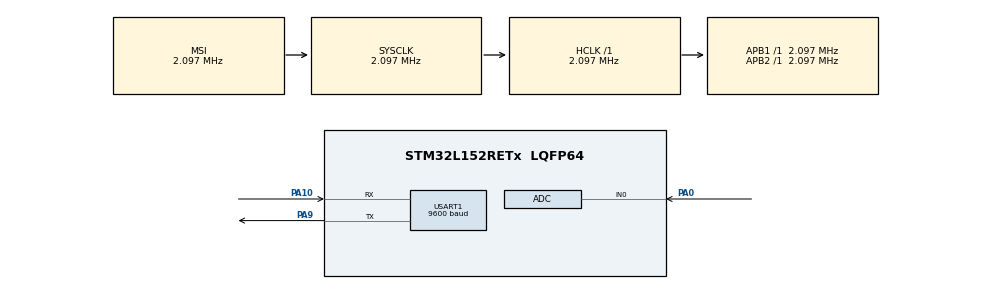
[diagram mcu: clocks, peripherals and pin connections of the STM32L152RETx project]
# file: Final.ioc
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ADC.Channel-0\#ChannelRegularConversion=ADC_CHANNEL_0
ADC.ChannelsBank=ADC_CHANNELS_BANK_A
ADC.ClockPrescaler=ADC_CLOCK_ASYNC_DIV1
ADC.ContinuousConvMode=DISABLE
ADC.DMAContinuousRequests=DISABLE
ADC.DataAlign=ADC_DATAALIGN_RIGHT
ADC.DiscontinuousConvMode=DISABLE
ADC.EOCSelection=ADC_EOC_SEQ_CONV
ADC.EnableAnalogWatchDog=false
ADC.ExternalTrigConv=ADC_SOFTWARE_START
ADC.ExternalTrigConvEdge=ADC_EXTERNALTRIGCONVEDGE_NONE
ADC.InjNumberOfConversion=0
ADC.LowPowerAutoPowerOff=ADC_AUTOPOWEROFF_DISABLE
ADC.LowPowerAutoWait=ADC_AUTOWAIT_DISABLE
ADC.NbrOfConversion=1
ADC.NbrOfConversionFlag=1
ADC.Rank-0\#ChannelRegularConversion=1
ADC.Resolution=ADC_RESOLUTION_10B
ADC.SamplingTime-0\#ChannelRegularConversion=ADC_SAMPLETIME_4CYCLES
ADC.ScanConvMode=ADC_SCAN_DISABLE
Mcu.Family=STM32L1
Mcu.Name=STM32L152RETx
Mcu.Package=LQFP64
NVIC.PriorityGroup=NVIC_PRIORITYGROUP_4
NVIC.RCC_IRQn=true\:0\:0\:false\:false\:true\:true
PA0-WKUP1.Mode=IN0
PA0-WKUP1.Signal=ADC_IN0
PA10.Mode=Asynchronous
PA10.Signal=USART1_RX
PA13.Mode=Serial_Wire
PA13.Signal=SYS_JTMS-SWDIO
PA14.Mode=Serial_Wire
PA14.Signal=SYS_JTCK-SWCLK
PA9.Mode=Asynchronous
PA9.Signal=USART1_TX
ProjectManager.HeapSize=0x200
ProjectManager.StackSize=0x400
ProjectManager.TargetToolchain=MDK-ARM V5
RCC.AHBFreq_Value=2097000
RCC.APB1Freq_Value=2097000
RCC.APB2Freq_Value=2097000
RCC.HSE_VALUE=24000000
RCC.HSI_VALUE=16000000
RCC.LSE_VALUE=32768
RCC.MSI_VALUE=2097000
RCC.SYSCLKFreq_VALUE=2097000
RCC.VCOOutputFreq_Value=48000000
USART1.BaudRate=9600
USART1.VirtualMode=VM_ASYNC
board=custom

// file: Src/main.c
/**
  ******************************************************************************
  * @file           : main.c
  * @brief          : Main program body
  ******************************************************************************
  ** This notice applies to any and all portions of this file
  * that are not between comment pairs USER CODE BEGIN and
  * USER CODE END. Other portions of this file, whether
  * inserted by the user or by software development tools
  * are owned by their respective copyright owners.
  *
  * COPYRIGHT(c) 2019 STMicroelectronics
  *
  * Redistribution and use in source and binary forms, with or without modification,
  * are permitted provided that the following conditions are met:
  *   1. Redistributions of source code must retain the above copyright notice,
  *      this list of conditions and the following disclaimer.
  *   2. Redistributions in binary form must reproduce the above copyright notice,
  *      this list of conditions and the following disclaimer in the documentation
  *      and/or other materials provided with the distribution.
  *   3. Neither the name of STMicroelectronics nor the names of its contributors
  *      may be used to endorse or promote products derived from this software
  *      without specific prior written permission.
  *
  * THIS SOFTWARE IS PROVIDED BY THE COPYRIGHT HOLDERS AND CONTRIBUTORS "AS IS"
  * AND ANY EXPRESS OR IMPLIED WARRANTIES, INCLUDING, BUT NOT LIMITED TO, THE
  * IMPLIED WARRANTIES OF MERCHANTABILITY AND FITNESS FOR A PARTICULAR PURPOSE ARE
  * DISCLAIMED. IN NO EVENT SHALL THE COPYRIGHT HOLDER OR CONTRIBUTORS BE LIABLE
  * FOR ANY DIRECT, INDIRECT, INCIDENTAL, SPECIAL, EXEMPLARY, OR CONSEQUENTIAL
  * DAMAGES (INCLUDING, BUT NOT LIMITED TO, PROCUREMENT OF SUBSTITUTE GOODS OR
  * SERVICES; LOSS OF USE, DATA, OR PROFITS; OR BUSINESS INTERRUPTION) HOWEVER
  * CAUSED AND ON ANY THEORY OF LIABILITY, WHETHER IN CONTRACT, STRICT LIABILITY,
  * OR TORT (INCLUDING NEGLIGENCE OR OTHERWISE) ARISING IN ANY WAY OUT OF THE USE
  * OF THIS SOFTWARE, EVEN IF ADVISED OF THE POSSIBILITY OF SUCH DAMAGE.
  *
  ******************************************************************************
  */
#include "main.h"
#include "stm32l1xx_hal.h"
#include "adc.h"
#include "usart.h"
#include "gpio.h"

/* USER CODE BEGIN Includes */
#include "stdio.h"
/* USER CODE END Includes */

/* USER CODE BEGIN PV */
/* Private variables ---------------------------------------------------------*/
#ifdef __GNU__
	#define PUTCHAR_PROTOTYPE int __io_putchar(int ch)
#else
	#define PUTCHAR_PROTOTYPE int fputc(int ch, FILE *f)
#endif

PUTCHAR_PROTOTYPE {
	HAL_UART_Transmit(&huart1, (uint8_t *)&ch, 1, 10);
	return ch;
}

uint16_t adcValue = 0;

//#define debug

/* USER CODE END PV */

void SystemClock_Config(void);

/* USER CODE BEGIN PFP */
/* Private function prototypes -----------------------------------------------*/

/* USER CODE END PFP */

int main(void)
{

  /* MCU Configuration----------------------------------------------------------*/

  /* Reset of all peripherals, Initializes the Flash interface and the Systick. */
  HAL_Init();

  /* Configure the system clock */
  SystemClock_Config();

  /* Initialize all configured peripherals */
  MX_GPIO_Init();
  MX_ADC_Init();
  MX_USART1_UART_Init();

  /* Infinite loop */
  while (1)
  {

  /* USER CODE BEGIN 3 */
		HAL_ADC_Start(&hadc);
		HAL_ADC_PollForConversion(&hadc, 100);
		adcValue = HAL_ADC_GetValue(&hadc);
		#ifdef debug
			printf("ADC value is %d \r\n", adcValue);
		#else
		printf("%d \r\n", adcValue);
		#endif
		HAL_Delay(3000);

  }
  /* USER CODE END 3 */

}

void SystemClock_Config(void)
{

  RCC_OscInitTypeDef RCC_OscInitStruct;
  RCC_ClkInitTypeDef RCC_ClkInitStruct;

    /**Configure the main internal regulator output voltage
    */
  __HAL_PWR_VOLTAGESCALING_CONFIG(PWR_REGULATOR_VOLTAGE_SCALE1);

    /**Initializes the CPU, AHB and APB busses clocks
    */
  RCC_OscInitStruct.OscillatorType = RCC_OSCILLATORTYPE_HSI|RCC_OSCILLATORTYPE_MSI;
  RCC_OscInitStruct.HSIState = RCC_HSI_ON;
  RCC_OscInitStruct.HSICalibrationValue = 16;
  RCC_OscInitStruct.MSIState = RCC_MSI_ON;
  RCC_OscInitStruct.MSICalibrationValue = 0;
  RCC_OscInitStruct.MSIClockRange = RCC_MSIRANGE_5;
  RCC_OscInitStruct.PLL.PLLState = RCC_PLL_NONE;
  if (HAL_RCC_OscConfig(&RCC_OscInitStruct) != HAL_OK)
  {
    _Error_Handler(__FILE__, __LINE__);
  }

    /**Initializes the CPU, AHB and APB busses clocks
    */
  RCC_ClkInitStruct.ClockType = RCC_CLOCKTYPE_HCLK|RCC_CLOCKTYPE_SYSCLK
                              |RCC_CLOCKTYPE_PCLK1|RCC_CLOCKTYPE_PCLK2;
  RCC_ClkInitStruct.SYSCLKSource = RCC_SYSCLKSOURCE_MSI;
  RCC_ClkInitStruct.AHBCLKDivider = RCC_SYSCLK_DIV1;
  RCC_ClkInitStruct.APB1CLKDivider = RCC_HCLK_DIV1;
  RCC_ClkInitStruct.APB2CLKDivider = RCC_HCLK_DIV1;

  if (HAL_RCC_ClockConfig(&RCC_ClkInitStruct, FLASH_LATENCY_0) != HAL_OK)
  {
    _Error_Handler(__FILE__, __LINE__);
  }

    /**Configure the Systick interrupt time
    */
  HAL_SYSTICK_Config(HAL_RCC_GetHCLKFreq()/1000);

    /**Configure the Systick
    */
  HAL_SYSTICK_CLKSourceConfig(SYSTICK_CLKSOURCE_HCLK);

  /* SysTick_IRQn interrupt configuration */
  HAL_NVIC_SetPriority(SysTick_IRQn, 0, 0);
}

void _Error_Handler(char *file, int line)
{
  while(1)
  {
  }
}

/************************ (C) COPYRIGHT STMicroelectronics *****END OF FILE****/
